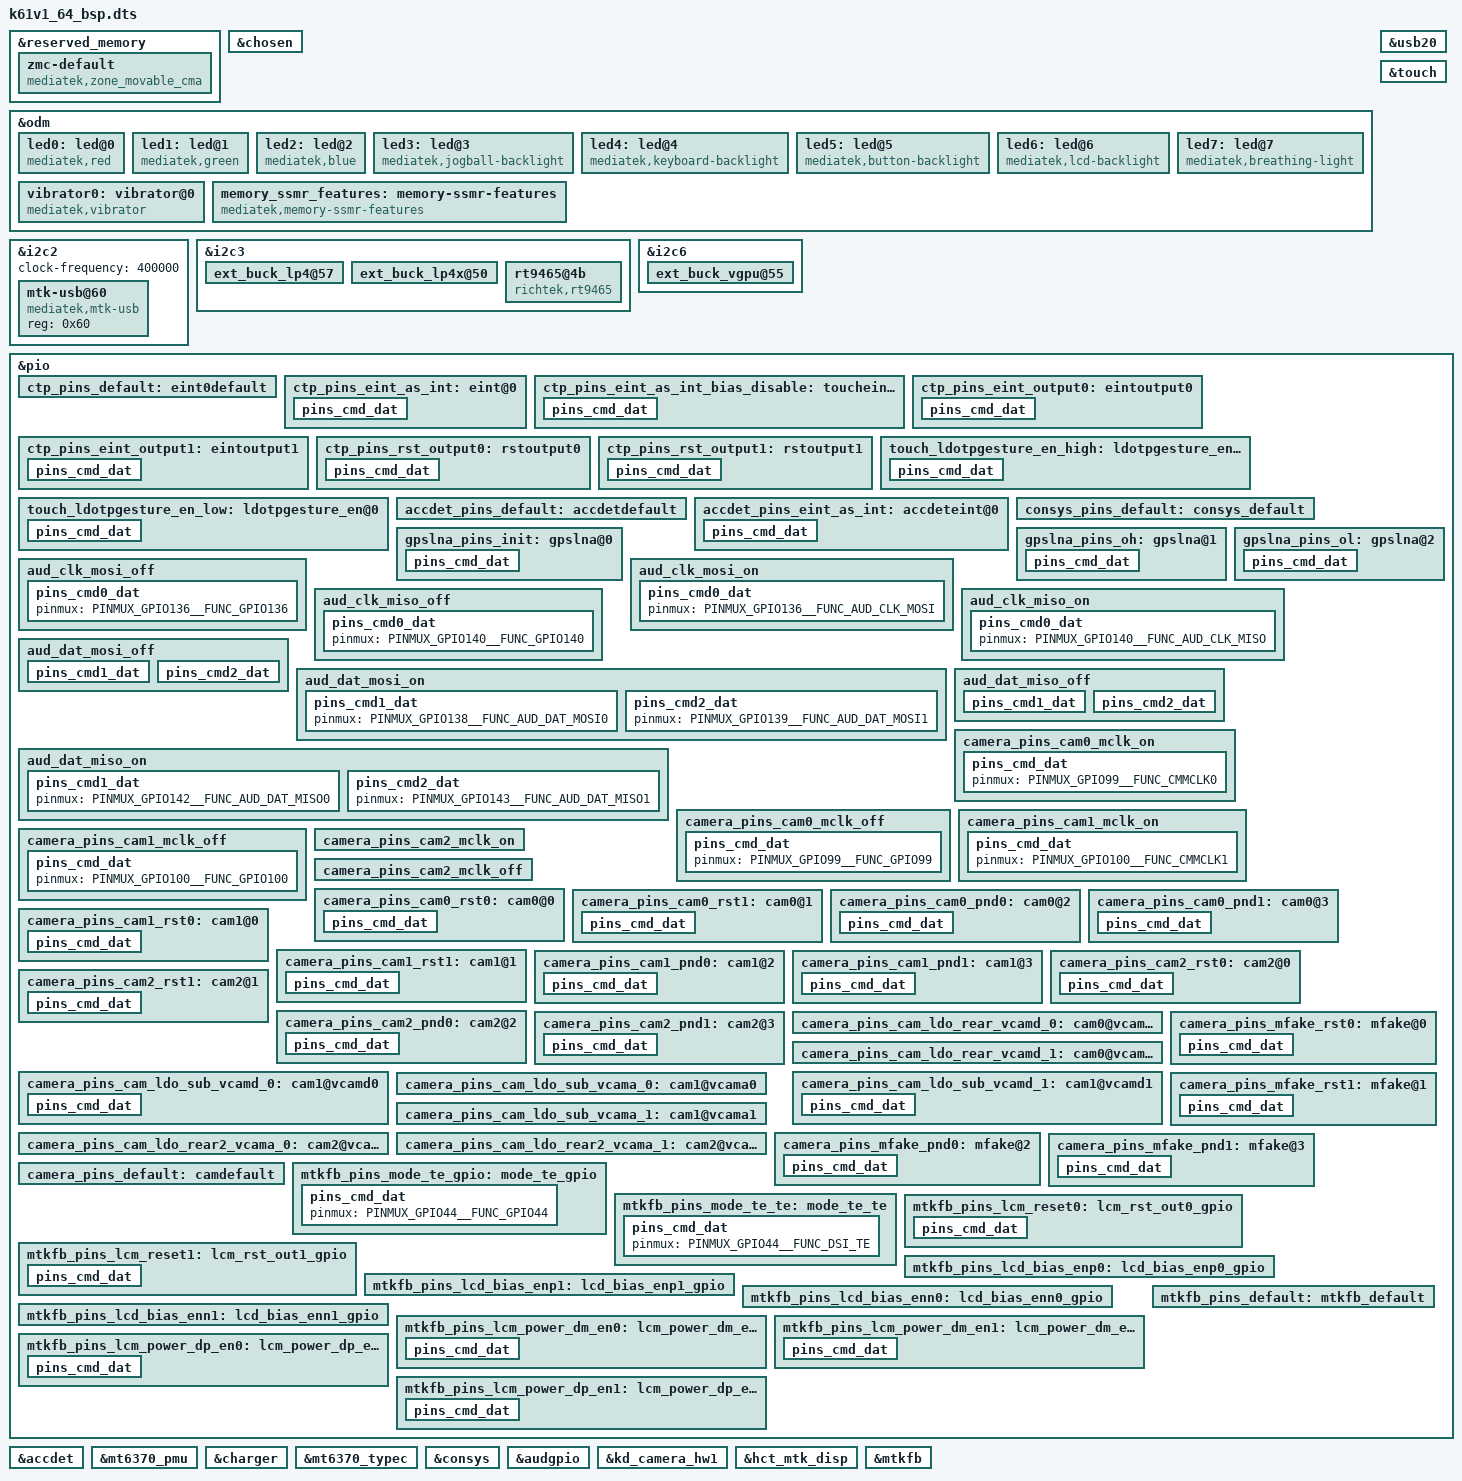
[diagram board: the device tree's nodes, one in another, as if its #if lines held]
#include <dt-bindings/interrupt-controller/arm-gic.h>
#include <dt-bindings/interrupt-controller/irq.h>
#include <dt-bindings/pinctrl/mt6761-pinfunc.h>
#include <dt-bindings/mmc/mt6761-msdc.h>
#include <dt-bindings/clock/mt6761-clk.h>
#include "hct_include/hct_project_all_config.h"
#include "hct_include/hct_board_dts_config.h"
/dts-v1/;
/plugin/;

&reserved_memory {
	#address-cells = <2>;
	#size-cells = <2>;
	ranges;

	zmc-default {
		compatible = "mediatek,zone_movable_cma";
		size = <0 0xffc00000>;
		alignment = <0 0x10000000>;
		alloc-ranges = <0 0xc0000000 1 0x00000000>;
	};
};

/* chosen */
&chosen {

	/* fpga may has no lk, we need to specify display info here */
	/* fb buffer is reserved using this dts by memory node above */
	atag,videolfb-fb_base_h = <0x0>;
	atag,videolfb-fb_base_l = <0x5e605000>;
	atag,videolfb-islcmfound = <1>;
	/* because no lk, so lcm is not inited */
	atag,videolfb-islcm_inited = <0>;
	atag,videolfb-fps= <6000>;
	atag,videolfb-vramSize= <0x017bb000>;
	atag,videolfb-lcmname= "nt35521_hd_dsi_vdo_truly_rt5081_drv";
};

&odm {
	led0:led@0 {
		compatible = "mediatek,red";
		led_mode = <__HCT_RED_LED_MODE__>;
#ifdef __HCT_RED_LED_DATA__
		data = <__HCT_RED_LED_DATA__>;
#else
		data = <1>;
#endif
		pwm_config = <0 0 0 0 0>;
	};
	led1:led@1 {
		compatible = "mediatek,green";
		led_mode = <__HCT_GREEN_LED_MODE__>;
#ifdef __HCT_GREEN_LED_DATA__
		data = <__HCT_GREEN_LED_DATA__>;
#else
		data = <1>;
#endif
		pwm_config = <0 0 0 0 0>;
	};
	led2:led@2 {
		compatible = "mediatek,blue";
		led_mode = <__HCT_BLUE_LED_MODE__>;
#ifdef __HCT_BLUE_LED_DATA__
		data = <__HCT_BLUE_LED_DATA__>;
#else
		data = <1>;
#endif
		pwm_config = <0 0 0 0 0>;
	};
	led3:led@3 {
		compatible = "mediatek,jogball-backlight";
		led_mode = <__HCT_JOGBALL_BACKLIGHT_LED_MODE__>;
		data = <1>;
		pwm_config = <0 0 0 0 0>;
	};
	led4:led@4 {
		compatible = "mediatek,keyboard-backlight";
		led_mode = <__HCT_KEYBOARD_BACKLIGHT_LED_MODE__>;
		data = <1>;
		pwm_config = <0 0 0 0 0>;
	};
	led5:led@5 {
		compatible = "mediatek,button-backlight";
		led_mode = <__HCT_BUTTON_BACKLIGHT_LED_MODE__>;
#ifdef __HCT_BUTTON_LED_DATA__
		data = <__HCT_BUTTON_LED_DATA__>;
#else
		data = <1>;
#endif
		pwm_config = <0 0 0 0 0>;
	};
	led6:led@6 {
		compatible = "mediatek,lcd-backlight";
		led_mode = <5>;
		data = <1>;
		pwm_config = <0 3 0 0 0>;
	};
    #if __HCT_BREATH_LIGHT_SUPPORT__
        led7:led@7 {
                compatible = "mediatek,breathing-light";
                led_mode = <__HCT_BREATHLIGHT_LED_MODE__>;
                data = <1>;
                pwm_config = <0 0 0 0 0>;
    };
    #endif
	vibrator0:vibrator@0 {
		compatible = "mediatek,vibrator";
		vib_timer = <25>;
		vib_limit = <9>;
		vib_vol= <9>;
	};
	memory_ssmr_features: memory-ssmr-features {
		compatible = "mediatek,memory-ssmr-features";
		svp-size = <0 0>;
		iris-recognition-size = <0 0>;
		2d_fr-size = <0 0>;
		tui-size = <0 0>;
		wfd-size = <0 0>;
		prot-sharedmem-size = <0 0>;
	};
};

&i2c2 {
	#address-cells = <1>;
	#size-cells = <0>;
	clock-frequency = <400000>;

	mtk-usb@60 {
		compatible = "mediatek,mtk-usb";
		reg = <0x60>;
		status = "okay";
	};
};

&i2c3 {
	ext_buck_lp4@57 {
		regulator-name ="ext_buck_vdd2";
		regulator-min-microvolt = <300000>;
		regulator-max-microvolt = <1300000>;
		vsel_pin = <0>;
	};

	ext_buck_lp4x@50 {
		regulator-name ="ext_buck_vddq";
		regulator-min-microvolt = <300000>;
		regulator-max-microvolt = <1300000>;
		vsel_pin = <1>;
	};
};

&i2c6 {
	ext_buck_vgpu@55 {
		regulator-name ="ext_buck_vgpu";
		regulator-min-microvolt = <300000>;
		regulator-max-microvolt = <1300000>;
		vsel_pin = <2>;
	};
};

//hct-drv add for wireless charge begin
#ifdef __HCT_WIRELESS_CHARGE_SUPPORT__
       #if __HCT_WIRELESS_CHARGE_SUPPORT__
&usb20 {
               wireless_charge_gpio = <&pio __HCT_WIRELESS_CHARGE_GPIO__ 0x0>;
               status = "okay";
};
       #endif
#endif
//hct-drv add for wireless charge end

/* TOUCH start */
&touch {
	tpd-resolution = <720 1440>;
	use-tpd-button = <1>;
	tpd-key-num = <3>;
	tpd-key-local= <139 172 158 0>;
	tpd-key-dim-local = <90 883 100 40 230
				 883 100 40 370 883 100 40 0 0 0 0>;
	tpd-max-touch-num = <5>;
	tpd-filter-enable = <1>;
	tpd-filter-pixel-density = <106>;
	tpd-filter-custom-prameters = <0 0 0 0 0 0 0 0 0 0 0 0>;
	tpd-filter-custom-speed = <0 0 0>;
	pinctrl-names = "default", "state_eint_as_int", "state_eint_output0",
		"state_eint_output1", "state_rst_output0", "state_rst_output1", "state_eint_as_int_bias_dis", "ldotpgesture_en_high", "ldotpgesture_en_low" ;
	pinctrl-0 = <&ctp_pins_default>;
	pinctrl-1 = <&ctp_pins_eint_as_int>;
	pinctrl-2 = <&ctp_pins_eint_output0>;
	pinctrl-3 = <&ctp_pins_eint_output1>;
	pinctrl-4 = <&ctp_pins_rst_output0>;
	pinctrl-5 = <&ctp_pins_rst_output1>;
	pinctrl-6 = <&ctp_pins_eint_as_int_bias_disable>;
    pinctrl-7 = <&touch_ldotpgesture_en_high>;
    pinctrl-8 = <&touch_ldotpgesture_en_low>;
	status = "okay";
};
&pio {
	ctp_pins_default: eint0default {
	};
	ctp_pins_eint_as_int: eint@0 {
		pins_cmd_dat {
			pinmux = <__HCT_CTP_EINT_ENT_PINNUX__>;
			slew-rate = <0>;
			bias-pull-up = <00>;
		};
	};
	ctp_pins_eint_as_int_bias_disable: toucheint_bias_dis{
		pins_cmd_dat {
			pinmux = <__HCT_CTP_EINT_ENT_PINNUX__>;
			slew-rate = <0>;
			bias-disable;
		};
	};
	ctp_pins_eint_output0: eintoutput0 {
		pins_cmd_dat {
			pinmux = <__HCT_CTP_EINT_ENT_PINNUX__>;
			slew-rate = <1>;
			output-low;
		};
	};
	ctp_pins_eint_output1: eintoutput1 {
		pins_cmd_dat {
			pinmux = <__HCT_CTP_EINT_ENT_PINNUX__>;
			slew-rate = <1>;
			output-high;
		};
	};
	ctp_pins_rst_output0: rstoutput0 {
		pins_cmd_dat {
			pinmux = <__HCT_CTP_RESET_PINNUX__>;
			slew-rate = <1>;
			output-low;
		};
	};
	ctp_pins_rst_output1: rstoutput1 {
		pins_cmd_dat {
			pinmux = <__HCT_CTP_RESET_PINNUX__>;
			slew-rate = <1>;
			output-high;
		};
	};
    touch_ldotpgesture_en_high: ldotpgesture_en@1 {
	#if defined(__HCT_LDO_TP_GESTURE_EN_PIN__)
        pins_cmd_dat {
                    pinmux = <__HCT_LDO_TP_GESTURE_EN_PIN__>;
                    slew-rate = <1>;
                    output-high;
            };
	#endif
    };
    touch_ldotpgesture_en_low: ldotpgesture_en@0 {
	#if defined(__HCT_LDO_TP_GESTURE_EN_PIN__)
        pins_cmd_dat {
                    pinmux = <__HCT_LDO_TP_GESTURE_EN_PIN__>;
                    slew-rate = <1>;
                    output-low;
		};
	#endif
	};
};
/* TOUCH end */
/* accdet start */
&accdet {
	accdet-mic-vol = <7>;
	headset-mode-setting = <0x500 0x500 1 0x1f0 0x800 0x800 0x20 0x44>;
	accdet-plugout-debounce = <1>;
	accdet-mic-mode = <__HCT_ACCDET_MIC_MODE__>;
	headset-eint-level-pol = <8>;
	headset-three-key-threshold = <0 80 220 400>;
	headset-three-key-threshold-CDD = <0 121 192 600>;
	headset-four-key-threshold = <0 58 121 192 400>;
	pinctrl-names = "default", "state_eint_as_int";
	pinctrl-0 = <&accdet_pins_default>;
	pinctrl-1 = <&accdet_pins_eint_as_int>;
#ifdef __HCT_TYPEC_ACCDET_MIC_SWITCH_GPIO_NUM__
	gpio-accdet-mic-switch = <&pio __HCT_TYPEC_ACCDET_MIC_SWITCH_GPIO_NUM__ 0x0>;
#endif
	status = "okay";
};
&pio {
	accdet_pins_default: accdetdefault {
	};
	accdet_pins_eint_as_int: accdeteint@0 {
		pins_cmd_dat {
			pinmux = <__HCT_ACCDET_EINT_PIN__>;
			slew-rate = <0>;
			bias-disable;
		};
	};
};
/* accdet end */
&mt6370_pmu {
	mt6370,intr_gpio_num = <11>; /* direct defined GPIO num */
	mt6370,intr_gpio = <&pio 11 0x0>;
};

&charger {
	algorithm_name = "SwitchCharging";
	chg1_ta_ac_charger_current = <2000000>;
	chg2_ta_ac_charger_current = <2000000>;
};

&i2c3 {
	rt9465@4b {
		compatible = "richtek,rt9465";
		reg = <0x4b>;
		status = "okay";
		rt,en_gpio_num = <176>;
		rt,en_gpio = <&pio 176 0x0>;
		rt,intr_gpio_num = <23>; /* direct defined GPIO num */
		rt,intr_gpio = <&pio 23 0x0>;
		interrupt-names = "wdtmri";
		charger_name = "secondary_chg";
		ichg = <1500000>; /* uA */
		mivr = <4500000>; /* uV */
		cv = <4550000>; /* uV */
		ieoc = <700000>; /* uA */
		safety_timer = <12>; /* hour */
		en_st; /* safety timer */
		/* en_te; */
		en_wdt;
	};
};

&mt6370_typec {
	mt6370pd,intr_gpio_num = <8>; /* direct defined GPIO num */
	mt6370pd,intr_gpio = <&pio 8 0x0>;
};
/* CONSYS GPIO standardization */
&pio {
	consys_pins_default: consys_default {
	};
	gpslna_pins_init: gpslna@0 {
		pins_cmd_dat {
			pinmux = <__HCT_GPS_LNA_EN_PINMUX__>;
			slew-rate = <0>;
			bias-disable;
			output-low;
		};
	};
	gpslna_pins_oh: gpslna@1 {
		pins_cmd_dat {
			pinmux = <__HCT_GPS_LNA_EN_PINMUX__>;
			slew-rate = <1>;
			output-high;
		};
	};
	gpslna_pins_ol: gpslna@2 {
		pins_cmd_dat {
			pinmux = <__HCT_GPS_LNA_EN_PINMUX__>;
			slew-rate = <1>;
			output-low;
		};
	};
};
&consys {
	pinctrl-names = "default", "gps_lna_state_init",
		"gps_lna_state_oh", "gps_lna_state_ol";
	pinctrl-0 = <&consys_pins_default>;
	pinctrl-1 = <&gpslna_pins_init>;
	pinctrl-2 = <&gpslna_pins_oh>;
	pinctrl-3 = <&gpslna_pins_ol>;
	status = "okay";
};
/* CONSYS end */

/* AUDIO GPIO standardization */
&audgpio {
	pinctrl-names = "aud_clk_mosi_off",
			"aud_clk_mosi_on",
			"aud_clk_miso_off",
			"aud_clk_miso_on",
			"aud_dat_mosi_off",
			"aud_dat_mosi_on",
			"aud_dat_miso_off",
			"aud_dat_miso_on"
			#if 0
			,
			"aud_smartpa_off",
			"aud_smartpa_on"
			#endif
			;
	pinctrl-0 = <&aud_clk_mosi_off>;
	pinctrl-1 = <&aud_clk_mosi_on>;
	pinctrl-2 = <&aud_clk_miso_off>;
	pinctrl-3 = <&aud_clk_miso_on>;
	pinctrl-4 = <&aud_dat_mosi_off>;
	pinctrl-5 = <&aud_dat_mosi_on>;
	pinctrl-6 = <&aud_dat_miso_off>;
	pinctrl-7 = <&aud_dat_miso_on>;
	#if 0
	pinctrl-8 = <&aud_pins_smartpa_off>;
	pinctrl-9 = <&aud_pins_smartpa_on>;
	#endif
#ifdef __HCT_EXTAMP_GPIO_NUM__
	gpio-extamp = <&pio __HCT_EXTAMP_GPIO_NUM__ 0x0>;
#endif
	status = "okay";
};

&pio {
	aud_clk_mosi_off: aud_clk_mosi_off {
		pins_cmd0_dat {
			pinmux = <PINMUX_GPIO136__FUNC_GPIO136>;
		};
	};

	aud_clk_mosi_on: aud_clk_mosi_on {
		pins_cmd0_dat {
			pinmux = <PINMUX_GPIO136__FUNC_AUD_CLK_MOSI>;
		};
	};

	aud_clk_miso_off: aud_clk_miso_off {
		pins_cmd0_dat {
			pinmux = <PINMUX_GPIO140__FUNC_GPIO140>;
		};
	};

	aud_clk_miso_on: aud_clk_miso_on {
		pins_cmd0_dat {
			pinmux = <PINMUX_GPIO140__FUNC_AUD_CLK_MISO>;
		};
	};

	aud_dat_mosi_off: aud_dat_mosi_off {
		pins_cmd1_dat {
			pinmux = <PINMUX_GPIO138__FUNC_GPIO138>;
			input-enable;
			slew-rate = <0>;
			bias-disable;
		};
		pins_cmd2_dat {
			pinmux = <PINMUX_GPIO139__FUNC_GPIO139>;
			input-enable;
			slew-rate = <0>;
			bias-disable;
		};
	};

	aud_dat_mosi_on: aud_dat_mosi_on {
		pins_cmd1_dat {
			pinmux = <PINMUX_GPIO138__FUNC_AUD_DAT_MOSI0>;
		};
		pins_cmd2_dat {
			pinmux = <PINMUX_GPIO139__FUNC_AUD_DAT_MOSI1>;
		};
	};

	aud_dat_miso_off: aud_dat_miso_off {
		pins_cmd1_dat {
			pinmux = <PINMUX_GPIO142__FUNC_GPIO142>;
			input-enable;
			slew-rate = <0>;
			bias-disable;
		};
		pins_cmd2_dat {
			pinmux = <PINMUX_GPIO143__FUNC_GPIO143>;
			input-enable;
			slew-rate = <0>;
			bias-disable;
		};
	};

	aud_dat_miso_on: aud_dat_miso_on {
		pins_cmd1_dat {
			pinmux = <PINMUX_GPIO142__FUNC_AUD_DAT_MISO0>;
		};
		pins_cmd2_dat {
			pinmux = <PINMUX_GPIO143__FUNC_AUD_DAT_MISO1>;
		};
	};
#if 0
	aud_pins_smartpa_off: aud_pins_smartpa_off {
		pins_cmd0_dat {
			pinmux = <PINMUX_GPIO17__FUNC_GPIO17>;
		};
		pins_cmd1_dat {
			pinmux = <PINMUX_GPIO18__FUNC_GPIO18>;
		};
		pins_cmd2_dat {
			pinmux = <PINMUX_GPIO19__FUNC_GPIO19>;
		};
		pins_cmd3_dat {
			pinmux = <PINMUX_GPIO20__FUNC_GPIO20>;
		};
	};

	aud_pins_smartpa_on: aud_pins_smartpa_on {
		pins_cmd0_dat {
			pinmux = <PINMUX_GPIO17__FUNC_I2S0_DI>;
		};
		pins_cmd1_dat {
			pinmux = <PINMUX_GPIO18__FUNC_I2S3_BCK>;
		};
		pins_cmd2_dat {
			pinmux = <PINMUX_GPIO19__FUNC_I2S3_LRCK>;
		};
		pins_cmd3_dat {
			pinmux = <PINMUX_GPIO20__FUNC_I2S3_DO>;
		};
	};
#endif
};
/* AUDIO end */


&pio {
	camera_pins_cam0_mclk_on: camera_pins_cam0_mclk_on {
		pins_cmd_dat {
			pinmux = <PINMUX_GPIO99__FUNC_CMMCLK0>;
		};
	};
	camera_pins_cam0_mclk_off: camera_pins_cam0_mclk_off {
		pins_cmd_dat {
			pinmux = <PINMUX_GPIO99__FUNC_GPIO99>;
		};
	};
	camera_pins_cam1_mclk_on: camera_pins_cam1_mclk_on {
		pins_cmd_dat {
			pinmux = <PINMUX_GPIO100__FUNC_CMMCLK1>;
		};
	};
	camera_pins_cam1_mclk_off: camera_pins_cam1_mclk_off {
		pins_cmd_dat {
			pinmux = <PINMUX_GPIO100__FUNC_GPIO100>;
		};
	};
	camera_pins_cam2_mclk_on: camera_pins_cam2_mclk_on {
		//pins_cmd_dat {
		//	pinmux = <PINMUX_GPIO108__FUNC_CMMCLK2>;
		//};
	};
	camera_pins_cam2_mclk_off: camera_pins_cam2_mclk_off {
		//pins_cmd_dat {
		//	pinmux = <PINMUX_GPIO108__FUNC_GPIO108>;
		//};
	};
	camera_pins_cam0_rst0: cam0@0 {
		pins_cmd_dat {
			pinmux = <__HCT_GPIO_CAMERA_CMRST_PINMUX__>;
			slew-rate = <1>;
			output-low;
		};
	};
	camera_pins_cam0_rst1: cam0@1 {
		pins_cmd_dat {
			pinmux = <__HCT_GPIO_CAMERA_CMRST_PINMUX__>;
			slew-rate = <1>;
			output-high;
		};
	};
	camera_pins_cam0_pnd0: cam0@2 {
		pins_cmd_dat {
			pinmux = <__HCT_GPIO_CAMERA_CMPDN_PINMUX__>;
			slew-rate = <1>;
			output-low;
		};
	};
	camera_pins_cam0_pnd1: cam0@3 {
		pins_cmd_dat {
			pinmux = <__HCT_GPIO_CAMERA_CMPDN_PINMUX__>;
			slew-rate = <1>;
			output-high;
		};
	};
	camera_pins_cam1_rst0: cam1@0 {
#ifdef __HCT_GPIO_CAMERA_CMRST1_PINMUX__
		pins_cmd_dat {
			pinmux = <__HCT_GPIO_CAMERA_CMRST1_PINMUX__>;
			slew-rate = <1>;
			output-low;
		};
#endif
	};
	camera_pins_cam1_rst1: cam1@1 {
#ifdef __HCT_GPIO_CAMERA_CMRST1_PINMUX__
		pins_cmd_dat {
			pinmux = <__HCT_GPIO_CAMERA_CMRST1_PINMUX__>;
			slew-rate = <1>;
			output-high;
		};
#endif
	};
	camera_pins_cam1_pnd0: cam1@2 {
#ifdef __HCT_GPIO_CAMERA_CMPDN1_PINMUX__
		pins_cmd_dat {
			pinmux = <__HCT_GPIO_CAMERA_CMPDN1_PINMUX__>;
			slew-rate = <1>;
			output-low;
		};
#endif
	};
	camera_pins_cam1_pnd1: cam1@3 {
#ifdef __HCT_GPIO_CAMERA_CMPDN1_PINMUX__
		pins_cmd_dat {
			pinmux = <__HCT_GPIO_CAMERA_CMPDN1_PINMUX__>;
			slew-rate = <1>;
			output-high;
		};
#endif
	};
	camera_pins_cam2_rst0: cam2@0 {
#ifdef __HCT_GPIO_CAMERA_MAIN2_CMRST_PINMUX__
		pins_cmd_dat {
			pinmux = <__HCT_GPIO_CAMERA_MAIN2_CMRST_PINMUX__>;
			slew-rate = <1>;
			output-low;
		};
#endif
	};
	camera_pins_cam2_rst1: cam2@1 {
#ifdef __HCT_GPIO_CAMERA_MAIN2_CMRST_PINMUX__
		pins_cmd_dat {
			pinmux = <__HCT_GPIO_CAMERA_MAIN2_CMRST_PINMUX__>;
			slew-rate = <1>;
			output-high;
		};
#endif
	};
	camera_pins_cam2_pnd0: cam2@2 {
#ifdef __HCT_GPIO_CAMERA_MAIN2_CMPDN_PINMUX__
		pins_cmd_dat {
			pinmux = <__HCT_GPIO_CAMERA_MAIN2_CMPDN_PINMUX__>;
			slew-rate = <1>;
			output-low;
		};
#endif
	};
	camera_pins_cam2_pnd1: cam2@3 {
#ifdef __HCT_GPIO_CAMERA_MAIN2_CMPDN_PINMUX__
		pins_cmd_dat {
			pinmux = <__HCT_GPIO_CAMERA_MAIN2_CMPDN_PINMUX__>;
			slew-rate = <1>;
			output-high;
		};
#endif
	};
	camera_pins_cam_ldo_rear_vcamd_0: cam0@vcamd0 {
		//pins_cmd_dat {
		//	pinmux = <PINMUX_GPIO88__FUNC_GPIO88>;
		//	slew-rate = <1>;
		//	output-low;
		//};
	};
	camera_pins_cam_ldo_rear_vcamd_1: cam0@vcamd1 {
		//pins_cmd_dat {
		//	pinmux = <PINMUX_GPIO88__FUNC_GPIO88>;
		//	slew-rate = <1>;
		//	output-high;
		//};
	};
	camera_pins_cam_ldo_sub_vcamd_0: cam1@vcamd0 {
#ifdef __HCT_GPIO_CAMERA_LDO_EN_PINMUX__
		pins_cmd_dat {
			pinmux = <__HCT_GPIO_CAMERA_LDO_EN_PINMUX__>;
			slew-rate = <1>;
			output-low;
		};
#endif
	};
	camera_pins_cam_ldo_sub_vcamd_1: cam1@vcamd1 {
#ifdef __HCT_GPIO_CAMERA_LDO_EN_PINMUX__
		pins_cmd_dat {
			pinmux = <__HCT_GPIO_CAMERA_LDO_EN_PINMUX__>;
			slew-rate = <1>;
			output-high;
		};
#endif
	};
	camera_pins_cam_ldo_sub_vcama_0: cam1@vcama0 {
		//pins_cmd_dat {
		//	pinmux = <PINMUX_GPIO169__FUNC_GPIO169>;
		//	slew-rate = <1>;
		//	output-low;
		//};
	};
	camera_pins_cam_ldo_sub_vcama_1: cam1@vcama1 {
		//pins_cmd_dat {
		//	pinmux = <PINMUX_GPIO169__FUNC_GPIO169>;
		//	slew-rate = <1>;
		//	output-high;
		//};
	};
	camera_pins_cam_ldo_rear2_vcama_0: cam2@vcama0 {
		//pins_cmd_dat {
		//	pinmux = <PINMUX_GPIO159__FUNC_GPIO159>;
		//	slew-rate = <1>;
		//	output-low;
		//};
	};
	camera_pins_cam_ldo_rear2_vcama_1: cam2@vcama1 {
		//pins_cmd_dat {
		//	pinmux = <PINMUX_GPIO159__FUNC_GPIO159>;
		//	slew-rate = <1>;
		//	output-high;
		//};
	};
	camera_pins_mfake_rst0: mfake@0 {
		pins_cmd_dat {
			pinmux = <PINMUX_GPIO87__FUNC_GPIO87>;
			slew-rate = <1>;
			output-low;
		};
	};
	camera_pins_mfake_rst1: mfake@1 {
		pins_cmd_dat {
			pinmux = <PINMUX_GPIO87__FUNC_GPIO87>;
			slew-rate = <1>;
			output-high;
		};
	};
	camera_pins_mfake_pnd0: mfake@2 {
		pins_cmd_dat {
			pinmux = <PINMUX_GPIO160__FUNC_GPIO160>;
			slew-rate = <1>;
			output-low;
		};
	};
	camera_pins_mfake_pnd1: mfake@3 {
		pins_cmd_dat {
			pinmux = <PINMUX_GPIO160__FUNC_GPIO160>;
			slew-rate = <1>;
			output-high;
		};
	};
	camera_pins_default: camdefault {
	};

};

&kd_camera_hw1 {
	pinctrl-names = "default",
			"cam0_rst0",
			"cam0_rst1",
			"cam0_pnd0",
			"cam0_pnd1",
			"cam1_rst0",
			"cam1_rst1",
			"cam1_pnd0",
			"cam1_pnd1",
			"cam2_rst0",
			"cam2_rst1",
			"cam2_pnd0",
			"cam2_pnd1",
			"cam0_vcamd_on",
			"cam0_vcamd_off",
			"cam1_vcamd_on",
			"cam1_vcamd_off",
			"cam1_vcama_on",
			"cam1_vcama_off",
			"cam2_vcama_on",
			"cam2_vcama_off",
			"cam0_mclk_on",
			"cam0_mclk_off",
			"cam1_mclk_on",
			"cam1_mclk_off",
			"cam2_mclk_on",
			"cam2_mclk_off",
			"cam_mfake_rst0",
			"cam_mfake_rst1",
			"cam_mfake_pnd0",
			"cam_mfake_pnd1";

	pinctrl-0 = <&camera_pins_default>;
	pinctrl-1 = <&camera_pins_cam0_rst0>;
	pinctrl-2 = <&camera_pins_cam0_rst1>;
	pinctrl-3 = <&camera_pins_cam0_pnd0>;
	pinctrl-4 = <&camera_pins_cam0_pnd1>;
	pinctrl-5 = <&camera_pins_cam1_rst0>;
	pinctrl-6 = <&camera_pins_cam1_rst1>;
	pinctrl-7 = <&camera_pins_cam1_pnd0>;
	pinctrl-8 = <&camera_pins_cam1_pnd1>;
	pinctrl-9 = <&camera_pins_cam2_rst0>;
	pinctrl-10 = <&camera_pins_cam2_rst1>;
	pinctrl-11 = <&camera_pins_cam2_pnd0>;
	pinctrl-12 = <&camera_pins_cam2_pnd1>;
	pinctrl-13 = <&camera_pins_cam_ldo_rear_vcamd_1>;
	pinctrl-14 = <&camera_pins_cam_ldo_rear_vcamd_0>;
	pinctrl-15 = <&camera_pins_cam_ldo_sub_vcamd_1>;
	pinctrl-16 = <&camera_pins_cam_ldo_sub_vcamd_0>;
	pinctrl-17 = <&camera_pins_cam_ldo_sub_vcama_1>;
	pinctrl-18 = <&camera_pins_cam_ldo_sub_vcama_0>;
	pinctrl-19 = <&camera_pins_cam_ldo_rear2_vcama_1>;
	pinctrl-20 = <&camera_pins_cam_ldo_rear2_vcama_0>;
	pinctrl-21 = <&camera_pins_cam0_mclk_on>;
	pinctrl-22 = <&camera_pins_cam0_mclk_off>;
	pinctrl-23 = <&camera_pins_cam1_mclk_on>;
	pinctrl-24 = <&camera_pins_cam1_mclk_off>;
	pinctrl-25 = <&camera_pins_cam2_mclk_on>;
	pinctrl-26 = <&camera_pins_cam2_mclk_off>;
	pinctrl-27 = <&camera_pins_mfake_rst0>;
	pinctrl-28 = <&camera_pins_mfake_rst1>;
	pinctrl-29 = <&camera_pins_mfake_pnd0>;
	pinctrl-30 = <&camera_pins_mfake_pnd1>;
	status = "okay";

};
/* DISPSYS GPIO standardization */
&pio {

	mtkfb_pins_mode_te_gpio: mode_te_gpio {
		pins_cmd_dat {
			pinmux = <PINMUX_GPIO44__FUNC_GPIO44>;
		};
	};

	mtkfb_pins_mode_te_te: mode_te_te {
		pins_cmd_dat {
			pinmux = <PINMUX_GPIO44__FUNC_DSI_TE>;
		};
	};

	mtkfb_pins_lcm_reset0: lcm_rst_out0_gpio {
		pins_cmd_dat {
			pinmux = <PINMUX_GPIO45__FUNC_GPIO45>;
			slew-rate = <1>;
			output-low;
		};
	};

	mtkfb_pins_lcm_reset1: lcm_rst_out1_gpio {
		pins_cmd_dat {
			pinmux = <PINMUX_GPIO45__FUNC_GPIO45>;
			slew-rate = <1>;
			output-high;
		};
	};
	// ENP-5v / 2.8V
	mtkfb_pins_lcd_bias_enp0: lcd_bias_enp0_gpio {
#if __HCT_GPIO_LCM_POWER_ENP_PINMUX__==PUNMUX_GPIO_NONE_FUNC_NONE
#else
		pins_cmd_dat {
			pinmux = <__HCT_GPIO_LCM_POWER_ENP_PINMUX__>;
			slew-rate = <1>;
			output-low;
		};
#endif
	};

	mtkfb_pins_lcd_bias_enp1: lcd_bias_enp1_gpio {
#if __HCT_GPIO_LCM_POWER_ENP_PINMUX__==PUNMUX_GPIO_NONE_FUNC_NONE
#else
		pins_cmd_dat {
			pinmux = <__HCT_GPIO_LCM_POWER_ENP_PINMUX__>;
			slew-rate = <1>;
			output-high;
		};
#endif
	};
	// ENN+5v / 1.8V
	mtkfb_pins_lcd_bias_enn0: lcd_bias_enn0_gpio {
#if __HCT_GPIO_LCM_POWER_ENN_PINMUX__==PUNMUX_GPIO_NONE_FUNC_NONE
#else
		pins_cmd_dat {
			pinmux = <__HCT_GPIO_LCM_POWER_ENN_PINMUX__>;
			slew-rate = <1>;
			output-low;
		};
#endif
	};

	mtkfb_pins_lcd_bias_enn1: lcd_bias_enn1_gpio {
#if __HCT_GPIO_LCM_POWER_ENN_PINMUX__==PUNMUX_GPIO_NONE_FUNC_NONE
#else
		pins_cmd_dat {
			pinmux = <__HCT_GPIO_LCM_POWER_ENN_PINMUX__>;
			slew-rate = <1>;
			output-high;
		};
#endif
	};

	mtkfb_pins_lcm_power_dm_en0: lcm_power_dm_en0 {
		pins_cmd_dat {
			pinmux = <__HCT_GPIO_LCM_POWER_DM_PINMUX__>;
			slew-rate = <1>;
			output-low;
		};
	};
	mtkfb_pins_lcm_power_dm_en1: lcm_power_dm_en1 {
		pins_cmd_dat {
			pinmux = <__HCT_GPIO_LCM_POWER_DM_PINMUX__>;
			slew-rate = <1>;
			output-high;
		};
	};
	mtkfb_pins_lcm_power_dp_en0: lcm_power_dp_en0 {
		pins_cmd_dat {
			pinmux = <__HCT_GPIO_LCM_POWER_DP_PINMUX__>;
			slew-rate = <1>;
			output-low;
		};
	};
	mtkfb_pins_lcm_power_dp_en1: lcm_power_dp_en1 {
		pins_cmd_dat {
			pinmux = <__HCT_GPIO_LCM_POWER_DP_PINMUX__>;
			slew-rate = <1>;
			output-high;
		};
	};

	mtkfb_pins_default: mtkfb_default {
	};

};


&hct_mtk_disp {
	pinctrl-names = "mode_te_gpio", "mode_te_te", "lcm_rst_out0_gpio",
		"lcm_rst_out1_gpio", "lcd_bias_enp0_gpio", "lcd_bias_enp1_gpio",
		"lcd_bias_enn0_gpio","lcd_bias_enn1_gpio","lcm_power_dm_en0",
		"lcm_power_dm_en1","lcm_power_dp_en0","lcm_power_dp_en1",
		"tp_incell_rst0_gpio", "tp_incell_rst1_gpio";
	pinctrl-0 = <&mtkfb_pins_mode_te_gpio>;
	pinctrl-1 = <&mtkfb_pins_mode_te_te>;
	pinctrl-2 = <&mtkfb_pins_lcm_reset0>;
	pinctrl-3 = <&mtkfb_pins_lcm_reset1>;
	pinctrl-4 = <&mtkfb_pins_lcd_bias_enp0>;
	pinctrl-5 = <&mtkfb_pins_lcd_bias_enp1>;
	pinctrl-6 = <&mtkfb_pins_lcd_bias_enn0>;
	pinctrl-7 = <&mtkfb_pins_lcd_bias_enn1>;
	pinctrl-8 = <&mtkfb_pins_lcm_power_dm_en0>;
	pinctrl-9 = <&mtkfb_pins_lcm_power_dm_en1>;
	pinctrl-10 = <&mtkfb_pins_lcm_power_dp_en0>;
	pinctrl-11 = <&mtkfb_pins_lcm_power_dp_en1>;
	pinctrl-12 = <&ctp_pins_rst_output0>;
        pinctrl-13 = <&ctp_pins_rst_output1>;
	status = "okay";
};

&mtkfb {
	pinctrl-names = "default", "mode_te_gpio", "mode_te_te", "lcm_rst_out0_gpio",
	"lcm_rst_out1_gpio", "lcd_bias_enp0_gpio", "lcd_bias_enp1_gpio", "lcd_bias_enn0_gpio", "lcd_bias_enn1_gpio",
	"tp_incell_rst0_gpio", "tp_incell_rst1_gpio";
	pinctrl-0 = <&mtkfb_pins_default>;
	pinctrl-1 = <&mtkfb_pins_mode_te_gpio>;
	pinctrl-2 = <&mtkfb_pins_mode_te_te>;
	pinctrl-3 = <&mtkfb_pins_lcm_reset0>;
	pinctrl-4 = <&mtkfb_pins_lcm_reset1>;
	pinctrl-5 = <&mtkfb_pins_lcd_bias_enp0>;
	pinctrl-6 = <&mtkfb_pins_lcd_bias_enp1>;
	pinctrl-7 = <&mtkfb_pins_lcd_bias_enn0>;
	pinctrl-8 = <&mtkfb_pins_lcd_bias_enn1>;
	pinctrl-9 = <&ctp_pins_rst_output0>;
	pinctrl-10 = <&ctp_pins_rst_output1>;
	status = "okay";
};/* DISPSYS GPIO standardization end */

#include <k61v1_64_bsp/cust.dtsi>
/*End of this file, DO NOT ADD ANYTHING HERE*/
